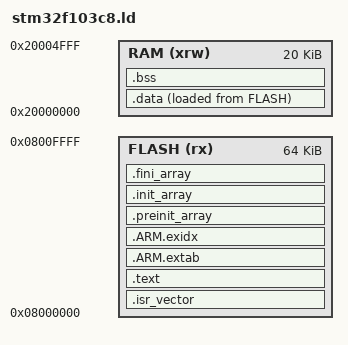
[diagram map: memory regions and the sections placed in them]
/* STM32F103C8: 64 KiB flash, 20 KiB SRAM. */
ENTRY(Reset_Handler)

MEMORY
{
    FLASH (rx) : ORIGIN = 0x08000000, LENGTH = 64K
    RAM (xrw)  : ORIGIN = 0x20000000, LENGTH = 20K
}

_estack = ORIGIN(RAM) + LENGTH(RAM);

PHDRS
{
    flash PT_LOAD FLAGS(5);
    ram PT_LOAD FLAGS(6);
}

SECTIONS
{
    .isr_vector : { KEEP(*(.isr_vector)) } > FLASH :flash

    .text :
    {
        *(.text .text.*)
        *(.rodata .rodata.*)
        KEEP(*(.init))
        KEEP(*(.fini))
        . = ALIGN(4);
    } > FLASH :flash

    .ARM.extab : { *(.ARM.extab* .gnu.linkonce.armextab.*) } > FLASH :flash
    .ARM.exidx :
    {
        __exidx_start = .;
        *(.ARM.exidx* .gnu.linkonce.armexidx.*)
        __exidx_end = .;
    } > FLASH :flash

    .preinit_array :
    {
        PROVIDE_HIDDEN(__preinit_array_start = .);
        KEEP(*(.preinit_array))
        PROVIDE_HIDDEN(__preinit_array_end = .);
    } > FLASH :flash

    .init_array :
    {
        PROVIDE_HIDDEN(__init_array_start = .);
        KEEP(*(SORT(.init_array.*)))
        KEEP(*(.init_array))
        PROVIDE_HIDDEN(__init_array_end = .);
    } > FLASH :flash

    .fini_array :
    {
        PROVIDE_HIDDEN(__fini_array_start = .);
        KEEP(*(SORT(.fini_array.*)))
        KEEP(*(.fini_array))
        PROVIDE_HIDDEN(__fini_array_end = .);
    } > FLASH :flash

    _sidata = LOADADDR(.data);
    .data :
    {
        . = ALIGN(4);
        _sdata = .;
        *(.data .data.*)
        . = ALIGN(4);
        _edata = .;
    } > RAM AT > FLASH :ram

    .bss (NOLOAD) :
    {
        . = ALIGN(4);
        _sbss = .;
        *(.bss .bss.* COMMON)
        . = ALIGN(8);
        _ebss = .;
    } > RAM :ram

    PROVIDE(end = .);
    PROVIDE(_end = .);
    ASSERT(_ebss + 0x400 <= _estack, "Insufficient space for stack")
}
